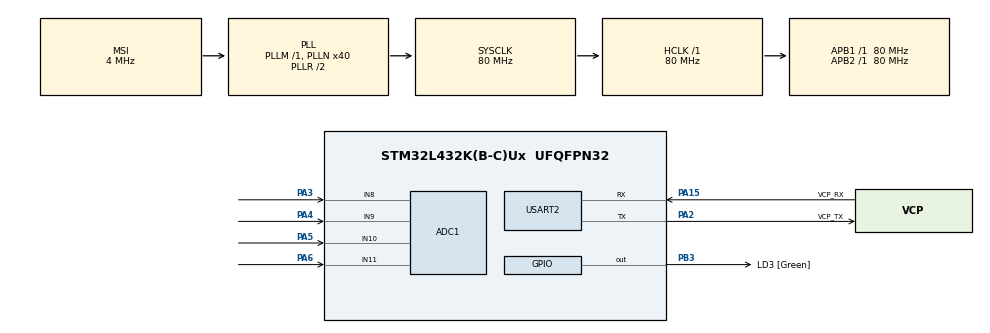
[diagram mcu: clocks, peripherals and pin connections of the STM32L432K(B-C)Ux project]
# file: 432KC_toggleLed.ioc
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Mcu.Family=STM32L4
RCC.CortexFreq_Value=80000000
ADC1.ContinuousConvMode=ENABLE
ADC1.OffsetNumber-10\#ChannelRegularConversion=ADC_OFFSET_NONE
PA0.GPIO_Label=MCO [High speed clock in]
PA15\ (JTDI).Signal=USART2_RX
PC15-OSC32_OUT\ (PC15).Mode=LSE-External-Oscillator
ADC1.Channel-8\#ChannelRegularConversion=ADC_CHANNEL_8
RCC.SYSCLKSource=RCC_SYSCLKSOURCE_PLLCLK
ProjectManager.StackSize=0x400
PB3\ (JTDO-TRACESWO).Signal=GPIO_Output
PC14-OSC32_IN\ (PC14).Mode=LSE-External-Oscillator
PA14\ (JTCK-SWCLK).Signal=SYS_JTCK-SWCLK
PA15\ (JTDI).Mode=Asynchronous
ADC1.Rank-11\#ChannelRegularConversion=4
RCC.HCLKFreq_Value=80000000
RCC.APB2TimFreq_Value=80000000
Dma.ADC1.0.Direction=DMA_PERIPH_TO_MEMORY
Dma.ADC1.0.MemDataAlignment=DMA_MDATAALIGN_WORD
RCC.AHBFreq_Value=80000000
RCC.HSE_VALUE=8000000
USART2.VirtualMode-Asynchronous=VM_ASYNC
ADC1.OffsetNumber-9\#ChannelRegularConversion=ADC_OFFSET_NONE
RCC.PLLMUL=RCC_PLLMUL_4
Dma.ADC1.0.PeriphInc=DMA_PINC_DISABLE
PA0.Mode=HSE-External-Clock-Source-for-LittleOrca
SH.ADCx_IN8.0=ADC1_IN8,IN8-Single-Ended
ADC1.OffsetNumber-11\#ChannelRegularConversion=ADC_OFFSET_NONE
PA0.Signal=RCC_CK_IN
Mcu.Package=UFQFPN32
ADC1.SamplingTime-11\#ChannelRegularConversion=ADC_SAMPLETIME_640CYCLES_5
PA6.Signal=ADCx_IN11
PA2.GPIO_Label=VCP_TX
ADC1.Channel-11\#ChannelRegularConversion=ADC_CHANNEL_11
SH.ADCx_IN9.0=ADC1_IN9,IN9-Single-Ended
RCC.APB1TimFreq_Value=80000000
PA13\ (JTMS-SWDIO).Signal=SYS_JTMS-SWDIO
Dma.Request0=ADC1
ADC1.SamplingTime-8\#ChannelRegularConversion=ADC_SAMPLETIME_640CYCLES_5
RCC.HSI48_VALUE=48000000
RCC.PLLSAI1N=16
PA3.Signal=ADCx_IN8
RCC.MSI_VALUE=4000000
ADC1.Channel-10\#ChannelRegularConversion=ADC_CHANNEL_10
PA14\ (JTCK-SWCLK).Mode=Serial_Wire
Dma.ADC1.0.Instance=DMA1_Channel1
ADC1.Rank-10\#ChannelRegularConversion=3
ADC1.Rank-8\#ChannelRegularConversion=1
PC15-OSC32_OUT\ (PC15).Signal=RCC_OSC32_OUT
PA14\ (JTCK-SWCLK).GPIO_Label=SWCLK
PB3\ (JTDO-TRACESWO).GPIO_Label=LD3 [Green]
RCC.HSI16_VALUE=16000000
Dma.ADC1.0.PeriphDataAlignment=DMA_PDATAALIGN_WORD
ProjectManager.TargetToolchain=STM32CubeIDE
ADC1.OffsetNumber-8\#ChannelRegularConversion=ADC_OFFSET_NONE
Dma.ADC1.0.Mode=DMA_CIRCULAR
Dma.ADC1.0.Priority=DMA_PRIORITY_HIGH
RCC.USBFreq_Value=32000000
PA5.Signal=ADCx_IN10
board=NUCLEO-L432KC
RCC.VCOOutputFreq_Value=160000000
RCC.APB2Freq_Value=80000000
SH.ADCx_IN11.0=ADC1_IN11,IN11-Single-Ended
PA13\ (JTMS-SWDIO).GPIO_Label=SWDIO
RCC.ADCFreq_Value=32000000
ADC1.SamplingTime-10\#ChannelRegularConversion=ADC_SAMPLETIME_640CYCLES_5
ADC1.DMAContinuousRequests=ENABLE
ADC1.Rank-9\#ChannelRegularConversion=2
ADC1.NbrOfConversion=4
PA15\ (JTDI).GPIO_Label=VCP_RX
Mcu.Name=STM32L432K(B-C)Ux
PA2.Signal=USART2_TX
ADC1.Channel-9\#ChannelRegularConversion=ADC_CHANNEL_9
PA13\ (JTMS-SWDIO).Mode=Serial_Wire
PA4.Signal=ADCx_IN9
RCC.SYSCLKFreq_VALUE=80000000
ADC1.master=1
PC14-OSC32_IN\ (PC14).Signal=RCC_OSC32_IN
Dma.ADC1.0.MemInc=DMA_MINC_ENABLE
SH.ADCx_IN10.0=ADC1_IN10,IN10-Single-Ended
ProjectManager.HeapSize=0x200
RCC.HSI_VALUE=16000000
NVIC.PriorityGroup=NVIC_PRIORITYGROUP_4
ADC1.NbrOfConversionFlag=1
RCC.PLLN=40
PA2.Mode=Asynchronous
ADC1.SamplingTime-9\#ChannelRegularConversion=ADC_SAMPLETIME_640CYCLES_5
NVIC.DMA1_Channel1_IRQn=true\:0\:0\:false\:false\:true\:false\:true
RCC.APB1Freq_Value=80000000

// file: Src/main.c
/* USER CODE BEGIN Header */
/**
  ******************************************************************************
  * @file           : main.c
  * @brief          : Main program body
  ******************************************************************************
  * @attention
  *
  * <h2><center>&copy; Copyright (c) 2021 STMicroelectronics.
  * All rights reserved.</center></h2>
  *
  * This software component is licensed by ST under BSD 3-Clause license,
  * the "License"; You may not use this file except in compliance with the
  * License. You may obtain a copy of the License at:
  *                        opensource.org/licenses/BSD-3-Clause
  *
  ******************************************************************************
  */
/* USER CODE END Header */
#include "main.h"

ADC_HandleTypeDef hadc1;
DMA_HandleTypeDef hdma_adc1;

UART_HandleTypeDef huart2;

/* USER CODE BEGIN PV */
/* Private variables ---------------------------------------------------------*/

/* USER CODE END PV */

void SystemClock_Config(void);
static void MX_GPIO_Init(void);
static void MX_DMA_Init(void);
static void MX_USART2_UART_Init(void);
static void MX_ADC1_Init(void);
/* USER CODE BEGIN PFP */
/* Private function prototypes -----------------------------------------------*/

/* USER CODE END PFP */

int main(void)
{

  /* MCU Configuration--------------------------------------------------------*/

  /* Reset of all peripherals, Initializes the Flash interface and the Systick. */
  HAL_Init();

  /* Configure the system clock */
  SystemClock_Config();

  /* Initialize all configured peripherals */
  MX_GPIO_Init();
  MX_DMA_Init();
  MX_USART2_UART_Init();
  MX_ADC1_Init();

  /* Infinite loop */
  while (1)
  {

    /* USER CODE BEGIN 3 */
	  HAL_GPIO_TogglePin(LD3_GPIO_Port, LD3_Pin);
	  HAL_Delay(50);
	  printf("Test is %d\n",1);
  }
  /* USER CODE END 3 */
}

void SystemClock_Config(void)
{
  RCC_OscInitTypeDef RCC_OscInitStruct = {0};
  RCC_ClkInitTypeDef RCC_ClkInitStruct = {0};
  RCC_PeriphCLKInitTypeDef PeriphClkInit = {0};

  /** Configure LSE Drive Capability
  */
  HAL_PWR_EnableBkUpAccess();
  __HAL_RCC_LSEDRIVE_CONFIG(RCC_LSEDRIVE_LOW);
  /** Initializes the RCC Oscillators according to the specified parameters
  * in the RCC_OscInitTypeDef structure.
  */
  RCC_OscInitStruct.OscillatorType = RCC_OSCILLATORTYPE_LSE|RCC_OSCILLATORTYPE_MSI;
  RCC_OscInitStruct.LSEState = RCC_LSE_ON;
  RCC_OscInitStruct.MSIState = RCC_MSI_ON;
  RCC_OscInitStruct.MSICalibrationValue = 0;
  RCC_OscInitStruct.MSIClockRange = RCC_MSIRANGE_6;
  RCC_OscInitStruct.PLL.PLLState = RCC_PLL_ON;
  RCC_OscInitStruct.PLL.PLLSource = RCC_PLLSOURCE_MSI;
  RCC_OscInitStruct.PLL.PLLM = 1;
  RCC_OscInitStruct.PLL.PLLN = 40;
  RCC_OscInitStruct.PLL.PLLP = RCC_PLLP_DIV7;
  RCC_OscInitStruct.PLL.PLLQ = RCC_PLLQ_DIV2;
  RCC_OscInitStruct.PLL.PLLR = RCC_PLLR_DIV2;
  if (HAL_RCC_OscConfig(&RCC_OscInitStruct) != HAL_OK)
  {
    Error_Handler();
  }
  /** Initializes the CPU, AHB and APB buses clocks
  */
  RCC_ClkInitStruct.ClockType = RCC_CLOCKTYPE_HCLK|RCC_CLOCKTYPE_SYSCLK
                              |RCC_CLOCKTYPE_PCLK1|RCC_CLOCKTYPE_PCLK2;
  RCC_ClkInitStruct.SYSCLKSource = RCC_SYSCLKSOURCE_PLLCLK;
  RCC_ClkInitStruct.AHBCLKDivider = RCC_SYSCLK_DIV1;
  RCC_ClkInitStruct.APB1CLKDivider = RCC_HCLK_DIV1;
  RCC_ClkInitStruct.APB2CLKDivider = RCC_HCLK_DIV1;

  if (HAL_RCC_ClockConfig(&RCC_ClkInitStruct, FLASH_LATENCY_4) != HAL_OK)
  {
    Error_Handler();
  }
  PeriphClkInit.PeriphClockSelection = RCC_PERIPHCLK_USART2|RCC_PERIPHCLK_ADC;
  PeriphClkInit.Usart2ClockSelection = RCC_USART2CLKSOURCE_PCLK1;
  PeriphClkInit.AdcClockSelection = RCC_ADCCLKSOURCE_PLLSAI1;
  PeriphClkInit.PLLSAI1.PLLSAI1Source = RCC_PLLSOURCE_MSI;
  PeriphClkInit.PLLSAI1.PLLSAI1M = 1;
  PeriphClkInit.PLLSAI1.PLLSAI1N = 16;
  PeriphClkInit.PLLSAI1.PLLSAI1P = RCC_PLLP_DIV7;
  PeriphClkInit.PLLSAI1.PLLSAI1Q = RCC_PLLQ_DIV2;
  PeriphClkInit.PLLSAI1.PLLSAI1R = RCC_PLLR_DIV2;
  PeriphClkInit.PLLSAI1.PLLSAI1ClockOut = RCC_PLLSAI1_ADC1CLK;
  if (HAL_RCCEx_PeriphCLKConfig(&PeriphClkInit) != HAL_OK)
  {
    Error_Handler();
  }
  /** Configure the main internal regulator output voltage
  */
  if (HAL_PWREx_ControlVoltageScaling(PWR_REGULATOR_VOLTAGE_SCALE1) != HAL_OK)
  {
    Error_Handler();
  }
  /** Enable MSI Auto calibration
  */
  HAL_RCCEx_EnableMSIPLLMode();
}

static void MX_ADC1_Init(void)
{

  ADC_ChannelConfTypeDef sConfig = {0};

  /** Common config
  */
  hadc1.Instance = ADC1;
  hadc1.Init.ClockPrescaler = ADC_CLOCK_ASYNC_DIV1;
  hadc1.Init.Resolution = ADC_RESOLUTION_12B;
  hadc1.Init.DataAlign = ADC_DATAALIGN_RIGHT;
  hadc1.Init.ScanConvMode = ADC_SCAN_ENABLE;
  hadc1.Init.EOCSelection = ADC_EOC_SINGLE_CONV;
  hadc1.Init.LowPowerAutoWait = DISABLE;
  hadc1.Init.ContinuousConvMode = ENABLE;
  hadc1.Init.NbrOfConversion = 4;
  hadc1.Init.DiscontinuousConvMode = DISABLE;
  hadc1.Init.ExternalTrigConv = ADC_SOFTWARE_START;
  hadc1.Init.ExternalTrigConvEdge = ADC_EXTERNALTRIGCONVEDGE_NONE;
  hadc1.Init.DMAContinuousRequests = ENABLE;
  hadc1.Init.Overrun = ADC_OVR_DATA_PRESERVED;
  hadc1.Init.OversamplingMode = DISABLE;
  if (HAL_ADC_Init(&hadc1) != HAL_OK)
  {
    Error_Handler();
  }
  /** Configure Regular Channel
  */
  sConfig.Channel = ADC_CHANNEL_8;
  sConfig.Rank = ADC_REGULAR_RANK_1;
  sConfig.SamplingTime = ADC_SAMPLETIME_640CYCLES_5;
  sConfig.SingleDiff = ADC_SINGLE_ENDED;
  sConfig.OffsetNumber = ADC_OFFSET_NONE;
  sConfig.Offset = 0;
  if (HAL_ADC_ConfigChannel(&hadc1, &sConfig) != HAL_OK)
  {
    Error_Handler();
  }
  /** Configure Regular Channel
  */
  sConfig.Channel = ADC_CHANNEL_9;
  sConfig.Rank = ADC_REGULAR_RANK_2;
  if (HAL_ADC_ConfigChannel(&hadc1, &sConfig) != HAL_OK)
  {
    Error_Handler();
  }
  /** Configure Regular Channel
  */
  sConfig.Channel = ADC_CHANNEL_10;
  sConfig.Rank = ADC_REGULAR_RANK_3;
  if (HAL_ADC_ConfigChannel(&hadc1, &sConfig) != HAL_OK)
  {
    Error_Handler();
  }
  /** Configure Regular Channel
  */
  sConfig.Channel = ADC_CHANNEL_11;
  sConfig.Rank = ADC_REGULAR_RANK_4;
  if (HAL_ADC_ConfigChannel(&hadc1, &sConfig) != HAL_OK)
  {
    Error_Handler();
  }

}

static void MX_USART2_UART_Init(void)
{

  huart2.Instance = USART2;
  huart2.Init.BaudRate = 115200;
  huart2.Init.WordLength = UART_WORDLENGTH_8B;
  huart2.Init.StopBits = UART_STOPBITS_1;
  huart2.Init.Parity = UART_PARITY_NONE;
  huart2.Init.Mode = UART_MODE_TX_RX;
  huart2.Init.HwFlowCtl = UART_HWCONTROL_NONE;
  huart2.Init.OverSampling = UART_OVERSAMPLING_16;
  huart2.Init.OneBitSampling = UART_ONE_BIT_SAMPLE_DISABLE;
  huart2.AdvancedInit.AdvFeatureInit = UART_ADVFEATURE_NO_INIT;
  if (HAL_UART_Init(&huart2) != HAL_OK)
  {
    Error_Handler();
  }

}

static void MX_DMA_Init(void)
{

  /* DMA controller clock enable */
  __HAL_RCC_DMA1_CLK_ENABLE();

  /* DMA interrupt init */
  /* DMA1_Channel1_IRQn interrupt configuration */
  HAL_NVIC_SetPriority(DMA1_Channel1_IRQn, 0, 0);
  HAL_NVIC_EnableIRQ(DMA1_Channel1_IRQn);

}

static void MX_GPIO_Init(void)
{
  GPIO_InitTypeDef GPIO_InitStruct = {0};

  /* GPIO Ports Clock Enable */
  __HAL_RCC_GPIOC_CLK_ENABLE();
  __HAL_RCC_GPIOA_CLK_ENABLE();
  __HAL_RCC_GPIOB_CLK_ENABLE();

  /*Configure GPIO pin Output Level */
  HAL_GPIO_WritePin(LD3_GPIO_Port, LD3_Pin, GPIO_PIN_RESET);

  /*Configure GPIO pin : LD3_Pin */
  GPIO_InitStruct.Pin = LD3_Pin;
  GPIO_InitStruct.Mode = GPIO_MODE_OUTPUT_PP;
  GPIO_InitStruct.Pull = GPIO_NOPULL;
  GPIO_InitStruct.Speed = GPIO_SPEED_FREQ_LOW;
  HAL_GPIO_Init(LD3_GPIO_Port, &GPIO_InitStruct);

}

void Error_Handler(void)
{
  while(1)
  {
  }
}

/************************ (C) COPYRIGHT STMicroelectronics *****END OF FILE****/
